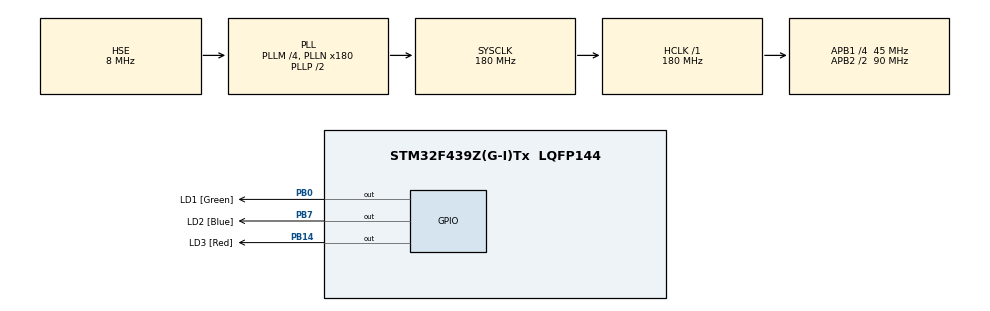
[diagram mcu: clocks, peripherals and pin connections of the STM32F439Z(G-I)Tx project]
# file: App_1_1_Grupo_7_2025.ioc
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Mcu.Family=STM32F4
Mcu.Name=STM32F439Z(G-I)Tx
Mcu.Package=LQFP144
NVIC.PriorityGroup=NVIC_PRIORITYGROUP_4
PB0.GPIO_Label=LD1 [Green]
PB0.Signal=GPIO_Output
PB14.GPIO_Label=LD3 [Red]
PB14.Signal=GPIO_Output
PB7.GPIO_Label=LD2 [Blue]
PB7.Signal=GPIO_Output
PH0/OSC_IN.Mode=HSE-External-Oscillator
PH0/OSC_IN.Signal=RCC_OSC_IN
PH1/OSC_OUT.Mode=HSE-External-Oscillator
PH1/OSC_OUT.Signal=RCC_OSC_OUT
ProjectManager.HeapSize=0x200
ProjectManager.StackSize=0x400
ProjectManager.TargetToolchain=STM32CubeIDE
RCC.48MHZClocksFreq_Value=51428571.428571425
RCC.AHBFreq_Value=180000000
RCC.APB1CLKDivider=RCC_HCLK_DIV4
RCC.APB1Freq_Value=45000000
RCC.APB1TimFreq_Value=90000000
RCC.APB2CLKDivider=RCC_HCLK_DIV2
RCC.APB2Freq_Value=90000000
RCC.APB2TimFreq_Value=180000000
RCC.CortexFreq_Value=180000000
RCC.HCLKFreq_Value=180000000
RCC.HSE_VALUE=8000000
RCC.HSI_VALUE=16000000
RCC.LSE_VALUE=32768
RCC.PLLM=4
RCC.PLLMUL=RCC_PLL_MUL9
RCC.PLLN=180
RCC.PLLQ=7
RCC.PLLSourceVirtual=RCC_PLLSOURCE_HSE
RCC.PRESCALERUSB=RCC_USBCLKSOURCE_PLL_DIV1_5
RCC.SYSCLKFreq_VALUE=180000000
RCC.SYSCLKSource=RCC_SYSCLKSOURCE_PLLCLK
RCC.SYSCLKSourceVirtual=RCC_SYSCLKSOURCE_PLLCLK
RCC.USBFreq_Value=48000000
RCC.VCOOutputFreq_Value=360000000
board=NUCLEO-F439ZI

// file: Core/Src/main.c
/* USER CODE BEGIN Header */
/**
 ******************************************************************************
 * @file           : main.c
 * @brief          : Main program body
 ******************************************************************************
 *
 *Alumnos:
 *Ballesteros, Gabriela Elizabeth
 *Tejerina, Damaris Carla Marianela
 *Mamani Flores, Carlos Alejandro
 ******************************************************************************
 */
/* USER CODE END Header */
#include "main.h"

/* USER CODE BEGIN PD */
#define n_leds 2			//cantidad de leds - 1
#define demora 200			//Etiqueta de tiempo para el delay
/* USER CODE END PD */

/* USER CODE BEGIN PV */
uint16_t Leds [10] = {LD1_Pin, LD2_Pin, LD3_Pin}; //Array de leds
uint8_t contador = 0;
/* USER CODE END PV */

void SystemClock_Config(void);
static void MX_GPIO_Init(void);

int main(void)
{

  /* MCU Configuration--------------------------------------------------------*/

  /* Reset of all peripherals, Initializes the Flash interface and the Systick. */
  HAL_Init();

  /* Configure the system clock */
  SystemClock_Config();

  /* Initialize all configured peripherals */
  MX_GPIO_Init();

  /* Infinite loop */
	while (1)
	{

    /* USER CODE BEGIN 3 */
		HAL_GPIO_WritePin(GPIOB, Leds[contador], GPIO_PIN_SET);			//Se ponen en estado alto las salidas conectadas a los leds
		HAL_Delay(demora);
		HAL_GPIO_WritePin(GPIOB, Leds[contador], GPIO_PIN_RESET);		//Se ponen en estado bajo las salidas conectadas a los leds
		HAL_Delay(demora);
//De tres formas diferentes se puede incrementar en uno el contador que esta inicializado en cero
		//contador = contador + 1;
		//contador += 1;
		contador++;

		if(contador > n_leds) contador = 0;			//Cuando el contador sea mayor a la cantidad de leds, el mismo se reinicia a cero

		//(contador > n_leds)?contador = 0:contador++; //if ternario que engloba todo lo anterior
	}
  /* USER CODE END 3 */
}

void SystemClock_Config(void)
{
  RCC_OscInitTypeDef RCC_OscInitStruct = {0};
  RCC_ClkInitTypeDef RCC_ClkInitStruct = {0};

  /** Configure the main internal regulator output voltage
  */
  __HAL_RCC_PWR_CLK_ENABLE();
  __HAL_PWR_VOLTAGESCALING_CONFIG(PWR_REGULATOR_VOLTAGE_SCALE1);

  /** Initializes the RCC Oscillators according to the specified parameters
  * in the RCC_OscInitTypeDef structure.
  */
  RCC_OscInitStruct.OscillatorType = RCC_OSCILLATORTYPE_HSE;
  RCC_OscInitStruct.HSEState = RCC_HSE_ON;
  RCC_OscInitStruct.PLL.PLLState = RCC_PLL_ON;
  RCC_OscInitStruct.PLL.PLLSource = RCC_PLLSOURCE_HSE;
  RCC_OscInitStruct.PLL.PLLM = 4;
  RCC_OscInitStruct.PLL.PLLN = 180;
  RCC_OscInitStruct.PLL.PLLP = RCC_PLLP_DIV2;
  RCC_OscInitStruct.PLL.PLLQ = 7;
  if (HAL_RCC_OscConfig(&RCC_OscInitStruct) != HAL_OK)
  {
    Error_Handler();
  }

  /** Activate the Over-Drive mode
  */
  if (HAL_PWREx_EnableOverDrive() != HAL_OK)
  {
    Error_Handler();
  }

  /** Initializes the CPU, AHB and APB buses clocks
  */
  RCC_ClkInitStruct.ClockType = RCC_CLOCKTYPE_HCLK|RCC_CLOCKTYPE_SYSCLK
                              |RCC_CLOCKTYPE_PCLK1|RCC_CLOCKTYPE_PCLK2;
  RCC_ClkInitStruct.SYSCLKSource = RCC_SYSCLKSOURCE_PLLCLK;
  RCC_ClkInitStruct.AHBCLKDivider = RCC_SYSCLK_DIV1;
  RCC_ClkInitStruct.APB1CLKDivider = RCC_HCLK_DIV4;
  RCC_ClkInitStruct.APB2CLKDivider = RCC_HCLK_DIV2;

  if (HAL_RCC_ClockConfig(&RCC_ClkInitStruct, FLASH_LATENCY_5) != HAL_OK)
  {
    Error_Handler();
  }
}

static void MX_GPIO_Init(void)
{
  GPIO_InitTypeDef GPIO_InitStruct = {0};

  /* GPIO Ports Clock Enable */
  __HAL_RCC_GPIOH_CLK_ENABLE();
  __HAL_RCC_GPIOB_CLK_ENABLE();

  /*Configure GPIO pin Output Level */
  HAL_GPIO_WritePin(GPIOB, LD1_Pin|LD3_Pin|LD2_Pin, GPIO_PIN_RESET);

  /*Configure GPIO pins : LD1_Pin LD3_Pin LD2_Pin */
  GPIO_InitStruct.Pin = LD1_Pin|LD3_Pin|LD2_Pin;
  GPIO_InitStruct.Mode = GPIO_MODE_OUTPUT_PP;
  GPIO_InitStruct.Pull = GPIO_NOPULL;
  GPIO_InitStruct.Speed = GPIO_SPEED_FREQ_LOW;
  HAL_GPIO_Init(GPIOB, &GPIO_InitStruct);

}

void Error_Handler(void)
{
	__disable_irq();
	while (1)
	{
	}
}
